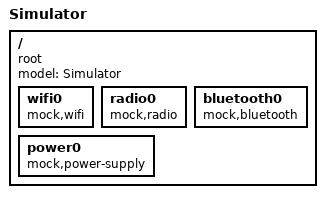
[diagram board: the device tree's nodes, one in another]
/dts-v1/;

#include <tactility/bindings/root.h>
#include <bindings/mock_wifi.h>
#include <bindings/mock_radio.h>
#include <bindings/mock_bluetooth.h>
#include <bindings/mock_power_supply.h>

/ {
	model = "Simulator";
	compatible = "root";

	wifi0 {
		compatible = "mock,wifi";
	};

	radio0 {
		compatible = "mock,radio";
	};

	bluetooth0 {
		compatible = "mock,bluetooth";
	};

	power0 {
		compatible = "mock,power-supply";
	};
};
